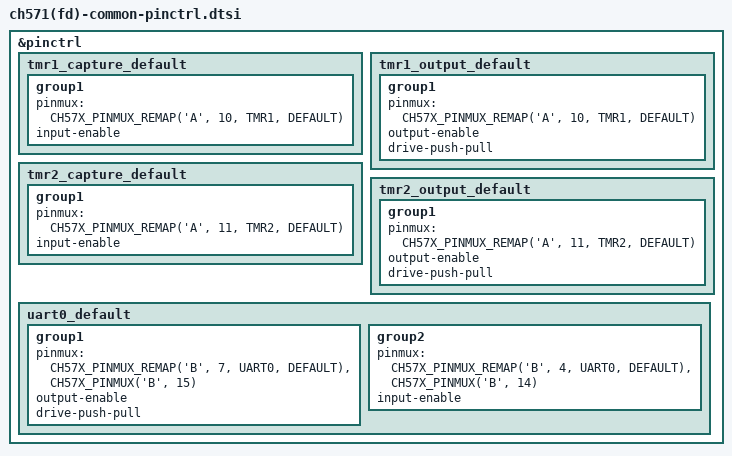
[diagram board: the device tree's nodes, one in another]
/*
 * Copyright (c) 2023 Chen Xingyu <hi@xingrz.me>
 * SPDX-License-Identifier: Apache-2.0
 */

#include <wch/ch57x/ch57x-common-pinctrl.dtsi>
#include <wch/ch57x/ch571-common-pinctrl.dtsi>
#include <wch/ch57x/ch571(fdr)-common-pinctrl.dtsi>

&pinctrl {
	/omit-if-no-ref/ tmr1_capture_default: tmr1_capture_default {
		group1 {
			pinmux = <CH57X_PINMUX_REMAP('A', 10, TMR1, DEFAULT)>; /* TMR1 */
			input-enable;
		};
	};

	/omit-if-no-ref/ tmr1_output_default: tmr1_output_default {
		group1 {
			pinmux = <CH57X_PINMUX_REMAP('A', 10, TMR1, DEFAULT)>; /* TMR1 */
			output-enable;
			drive-push-pull;
		};
	};

	/omit-if-no-ref/ tmr2_capture_default: tmr2_capture_default {
		group1 {
			pinmux = <CH57X_PINMUX_REMAP('A', 11, TMR2, DEFAULT)>; /* TMR2 */
			input-enable;
		};
	};

	/omit-if-no-ref/ tmr2_output_default: tmr2_output_default {
		group1 {
			pinmux = <CH57X_PINMUX_REMAP('A', 11, TMR2, DEFAULT)>; /* TMR2 */
			output-enable;
			drive-push-pull;
		};
	};

	/omit-if-no-ref/ uart0_default: uart0_default {
		group1 {
			pinmux = <CH57X_PINMUX_REMAP('B', 7, UART0, DEFAULT)>, /* TXD0 */
				 <CH57X_PINMUX('B', 15)>; /* DTR */
			output-enable;
			drive-push-pull;
		};
		group2 {
			pinmux = <CH57X_PINMUX_REMAP('B', 4, UART0, DEFAULT)>, /* RXD0 */
				 <CH57X_PINMUX('B', 14)>; /* DSR */
			input-enable;
		};
	};
};
